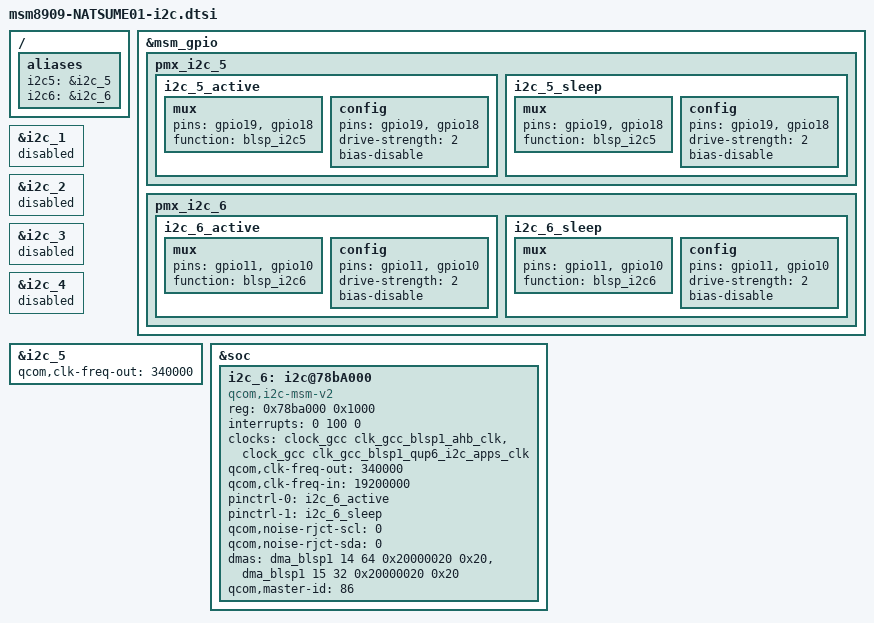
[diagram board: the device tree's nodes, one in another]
/*
 * This software is contributed or developed by KYOCERA Corporation.
 * (C) 2019 KYOCERA Corporation
 *
 * This program is free software; you can redistribute it and/or modify
 * it under the terms of the GNU General Public License version 2 and
 * only version 2 as published by the Free Software Foundation.
 *
 * This program is distributed in the hope that it will be useful,
 * but WITHOUT ANY WARRANTY; without even the implied warranty of
 * MERCHANTABILITY or FITNESS FOR A PARTICULAR PURPOSE.  See the
 * GNU General Public License for more details.
 */

&msm_gpio {
    /delete-node/ pmx_i2c_5;
    pmx_i2c_5 {
        i2c_5_active: i2c_5_active {
            mux {
                pins = "gpio19", "gpio18";
                function = "blsp_i2c5";
            };
            config {
                pins = "gpio19", "gpio18";
                drive-strength = <2>; /* 2 MA */
                bias-disable; /* No PULL */
            };
        };
        i2c_5_sleep: i2c_5_sleep {
            mux {
                pins = "gpio19", "gpio18";
                function = "blsp_i2c5";
            };
            config {
                pins = "gpio19", "gpio18";
                drive-strength = <2>; /* 2 MA */
                bias-disable; /* No PULL */
            };
        };
    };

    /delete-node/ pmx_i2c_6;
    pmx_i2c_6 {
        i2c_6_active: i2c_6_active {
            mux {
                pins = "gpio11", "gpio10";
                function = "blsp_i2c6";
            };
            config {
                pins = "gpio11", "gpio10";
                drive-strength = <2>; /* 2 MA */
                bias-disable; /* No PULL */
            };
        };
        i2c_6_sleep: i2c_6_sleep {
            mux {
                pins = "gpio11", "gpio10";
                function = "blsp_i2c6";
            };
            config {
                pins = "gpio11", "gpio10";
                drive-strength = <2>; /* 2 MA */
                bias-disable; /* No PULL */
            };
        };
    };
};

/ {
    aliases {
        i2c5 = &i2c_5;
        i2c6 = &i2c_6;
    };
};

&i2c_1 {
    status = "disabled";
};

&i2c_2 {
    status = "disabled";
};

&i2c_3 {
    status = "disabled";
};

&i2c_4 {
    status = "disabled";
};

&i2c_5 {
    qcom,clk-freq-out = <340000>;
    status = "ok";
};

&soc {
    i2c_6: i2c@78bA000 { /* BLSP1 QUP6 */
        compatible = "qcom,i2c-msm-v2";
        #address-cells = <1>;
        #size-cells = <0>;
        reg-names = "qup_phys_addr";
        reg = <0x78ba000 0x1000>;
        interrupt-names = "qup_irq";
        interrupts = <0 100 0>;
        clocks = <&clock_gcc clk_gcc_blsp1_ahb_clk>,
                 <&clock_gcc clk_gcc_blsp1_qup6_i2c_apps_clk>;
        clock-names = "iface_clk", "core_clk";
        qcom,clk-freq-out = <340000>;
        qcom,clk-freq-in  = <19200000>;
        pinctrl-names = "i2c_active", "i2c_sleep";
        pinctrl-0 = <&i2c_6_active>;
        pinctrl-1 = <&i2c_6_sleep>;
        qcom,noise-rjct-scl = <0>;
        qcom,noise-rjct-sda = <0>;
        dmas = <&dma_blsp1 14 64 0x20000020 0x20>,
               <&dma_blsp1 15 32 0x20000020 0x20>;
        dma-names = "tx", "rx";
        qcom,master-id = <86>;
        status = "ok";
    };
};

